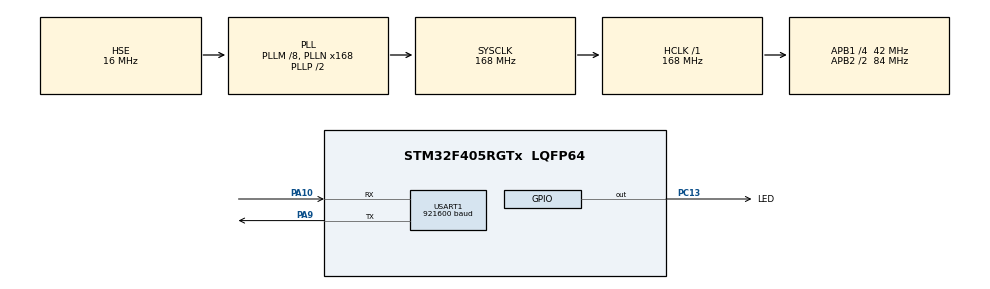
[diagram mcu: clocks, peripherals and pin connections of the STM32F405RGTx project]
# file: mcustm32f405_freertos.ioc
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FREERTOS.BinarySemaphores01=ledToggleSem,Dynamic,NULL;tickSem,Dynamic,NULL
FREERTOS.Events01=myEvent01,Dynamic,NULL
FREERTOS.Tasks01=defaultTask,24,128,StartDefaultTask,Default,NULL,Dynamic,NULL,NULL;ledTask,8,128,StartLedTask,Default,NULL,Dynamic,NULL,NULL;tickTask,8,128,StartTickTask,Default,NULL,Dynamic,NULL,NULL
FREERTOS.configUSE_NEWLIB_REENTRANT=1
Mcu.Family=STM32F4
Mcu.Name=STM32F405RGTx
Mcu.Package=LQFP64
NVIC.PriorityGroup=NVIC_PRIORITYGROUP_4
NVIC.TIM8_TRG_COM_TIM14_IRQn=true\:15\:0\:false\:false\:true\:false\:false\:true\:true
NVIC.TimeBase=TIM8_TRG_COM_TIM14_IRQn
NVIC.TimeBaseIP=TIM14
PA10.Mode=Asynchronous
PA10.Signal=USART1_RX
PA13.Mode=Trace_Asynchronous_SW
PA13.Signal=SYS_JTMS-SWDIO
PA14.Mode=Trace_Asynchronous_SW
PA14.Signal=SYS_JTCK-SWCLK
PA9.Mode=Asynchronous
PA9.Signal=USART1_TX
PB3.Mode=Trace_Asynchronous_SW
PB3.Signal=SYS_JTDO-SWO
PC13-ANTI_TAMP.GPIO_Label=LED
PC13-ANTI_TAMP.PinState=GPIO_PIN_SET
PC13-ANTI_TAMP.Signal=GPIO_Output
PH0-OSC_IN.Mode=HSE-External-Oscillator
PH0-OSC_IN.Signal=RCC_OSC_IN
PH1-OSC_OUT.Mode=HSE-External-Oscillator
PH1-OSC_OUT.Signal=RCC_OSC_OUT
ProjectManager.HeapSize=0x200
ProjectManager.StackSize=0x400
ProjectManager.TargetToolchain=STM32CubeIDE
RCC.48MHZClocksFreq_Value=84000000
RCC.AHBFreq_Value=168000000
RCC.APB1CLKDivider=RCC_HCLK_DIV4
RCC.APB1Freq_Value=42000000
RCC.APB1TimFreq_Value=84000000
RCC.APB2CLKDivider=RCC_HCLK_DIV2
RCC.APB2Freq_Value=84000000
RCC.APB2TimFreq_Value=168000000
RCC.CortexFreq_Value=168000000
RCC.HCLKFreq_Value=168000000
RCC.HSE_VALUE=16000000
RCC.HSI_VALUE=16000000
RCC.LSE_VALUE=32768
RCC.PLLM=8
RCC.PLLN=168
RCC.PLLSourceVirtual=RCC_PLLSOURCE_HSE
RCC.SYSCLKFreq_VALUE=168000000
RCC.SYSCLKSource=RCC_SYSCLKSOURCE_PLLCLK
RCC.VCOOutputFreq_Value=336000000
USART1.BaudRate=921600
USART1.VirtualMode=VM_ASYNC
VP_FREERTOS_VS_CMSIS_V2.Mode=CMSIS_V2
VP_SYS_VS_tim14.Mode=TIM14
board=custom

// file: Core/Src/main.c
/* USER CODE BEGIN Header */
/**
 ******************************************************************************
 * @file           : main.c
 * @brief          : Main program body
 ******************************************************************************
 * @attention
 *
 * Copyright (c) 2024 STMicroelectronics.
 * All rights reserved.
 *
 * This software is licensed under terms that can be found in the LICENSE file
 * in the root directory of this software component.
 * If no LICENSE file comes with this software, it is provided AS-IS.
 *
 ******************************************************************************
 */
/* USER CODE END Header */
#include "main.h"
#include "cmsis_os.h"

UART_HandleTypeDef huart1;

/* Definitions for defaultTask */
osThreadId_t defaultTaskHandle;
const osThreadAttr_t defaultTask_attributes = {
  .name = "defaultTask",
  .stack_size = 128 * 4,
  .priority = (osPriority_t) osPriorityNormal,
};
/* Definitions for ledTask */
osThreadId_t ledTaskHandle;
const osThreadAttr_t ledTask_attributes = {
  .name = "ledTask",
  .stack_size = 128 * 4,
  .priority = (osPriority_t) osPriorityLow,
};
/* Definitions for tickTask */
osThreadId_t tickTaskHandle;
const osThreadAttr_t tickTask_attributes = {
  .name = "tickTask",
  .stack_size = 128 * 4,
  .priority = (osPriority_t) osPriorityLow,
};
/* Definitions for ledToggleSem */
osSemaphoreId_t ledToggleSemHandle;
const osSemaphoreAttr_t ledToggleSem_attributes = {
  .name = "ledToggleSem"
};
/* Definitions for tickSem */
osSemaphoreId_t tickSemHandle;
const osSemaphoreAttr_t tickSem_attributes = {
  .name = "tickSem"
};
/* Definitions for myEvent01 */
osEventFlagsId_t myEvent01Handle;
const osEventFlagsAttr_t myEvent01_attributes = {
  .name = "myEvent01"
};

void SystemClock_Config(void);
static void MX_GPIO_Init(void);
static void MX_USART1_UART_Init(void);
void StartDefaultTask(void *argument);
void StartLedTask(void *argument);
void StartTickTask(void *argument);

/* USER CODE BEGIN 0 */

// Send printf to uart1
int _write(int fd, char *ptr, int len) {
    HAL_StatusTypeDef hstatus;

    if (fd == 1 || fd == 2) {
        hstatus = HAL_UART_Transmit(&huart1, (uint8_t*) ptr, len, HAL_MAX_DELAY);
        if (hstatus == HAL_OK)
            return len;
        else
            return -1;
    }
    return -1;
}

/* USER CODE END 0 */

int main(void)
{

  /* MCU Configuration--------------------------------------------------------*/

  /* Reset of all peripherals, Initializes the Flash interface and the Systick. */
  HAL_Init();

  /* Configure the system clock */
  SystemClock_Config();

  /* Initialize all configured peripherals */
  MX_GPIO_Init();
  MX_USART1_UART_Init();
  /* USER CODE BEGIN 2 */

    DBG("\n\n\n--------\nStarting\n");

  /* USER CODE END 2 */

  /* Init scheduler */
  osKernelInitialize();

  /* Create the semaphores(s) */
  /* creation of ledToggleSem */
  ledToggleSemHandle = osSemaphoreNew(1, 0, &ledToggleSem_attributes);

  /* creation of tickSem */
  tickSemHandle = osSemaphoreNew(1, 0, &tickSem_attributes);

  /* Create the thread(s) */
  /* creation of defaultTask */
  defaultTaskHandle = osThreadNew(StartDefaultTask, NULL, &defaultTask_attributes);

  /* creation of ledTask */
  ledTaskHandle = osThreadNew(StartLedTask, NULL, &ledTask_attributes);

  /* creation of tickTask */
  tickTaskHandle = osThreadNew(StartTickTask, NULL, &tickTask_attributes);

  /* Create the event(s) */
  /* creation of myEvent01 */
  myEvent01Handle = osEventFlagsNew(&myEvent01_attributes);

  /* Start scheduler */
  osKernelStart();

  /* We should never get here as control is now taken by the scheduler */
  /* Infinite loop */
    while (1)
    {

    }
}

void SystemClock_Config(void)
{
  RCC_OscInitTypeDef RCC_OscInitStruct = {0};
  RCC_ClkInitTypeDef RCC_ClkInitStruct = {0};

  /** Configure the main internal regulator output voltage
  */
  __HAL_RCC_PWR_CLK_ENABLE();
  __HAL_PWR_VOLTAGESCALING_CONFIG(PWR_REGULATOR_VOLTAGE_SCALE1);

  /** Initializes the RCC Oscillators according to the specified parameters
  * in the RCC_OscInitTypeDef structure.
  */
  RCC_OscInitStruct.OscillatorType = RCC_OSCILLATORTYPE_HSE;
  RCC_OscInitStruct.HSEState = RCC_HSE_ON;
  RCC_OscInitStruct.PLL.PLLState = RCC_PLL_ON;
  RCC_OscInitStruct.PLL.PLLSource = RCC_PLLSOURCE_HSE;
  RCC_OscInitStruct.PLL.PLLM = 8;
  RCC_OscInitStruct.PLL.PLLN = 168;
  RCC_OscInitStruct.PLL.PLLP = RCC_PLLP_DIV2;
  RCC_OscInitStruct.PLL.PLLQ = 4;
  if (HAL_RCC_OscConfig(&RCC_OscInitStruct) != HAL_OK)
  {
    Error_Handler();
  }

  /** Initializes the CPU, AHB and APB buses clocks
  */
  RCC_ClkInitStruct.ClockType = RCC_CLOCKTYPE_HCLK|RCC_CLOCKTYPE_SYSCLK
                              |RCC_CLOCKTYPE_PCLK1|RCC_CLOCKTYPE_PCLK2;
  RCC_ClkInitStruct.SYSCLKSource = RCC_SYSCLKSOURCE_PLLCLK;
  RCC_ClkInitStruct.AHBCLKDivider = RCC_SYSCLK_DIV1;
  RCC_ClkInitStruct.APB1CLKDivider = RCC_HCLK_DIV4;
  RCC_ClkInitStruct.APB2CLKDivider = RCC_HCLK_DIV2;

  if (HAL_RCC_ClockConfig(&RCC_ClkInitStruct, FLASH_LATENCY_5) != HAL_OK)
  {
    Error_Handler();
  }
}

static void MX_USART1_UART_Init(void)
{

  huart1.Instance = USART1;
  huart1.Init.BaudRate = 921600;
  huart1.Init.WordLength = UART_WORDLENGTH_8B;
  huart1.Init.StopBits = UART_STOPBITS_1;
  huart1.Init.Parity = UART_PARITY_NONE;
  huart1.Init.Mode = UART_MODE_TX_RX;
  huart1.Init.HwFlowCtl = UART_HWCONTROL_NONE;
  huart1.Init.OverSampling = UART_OVERSAMPLING_16;
  if (HAL_UART_Init(&huart1) != HAL_OK)
  {
    Error_Handler();
  }

}

static void MX_GPIO_Init(void)
{
  GPIO_InitTypeDef GPIO_InitStruct = {0};

  /* GPIO Ports Clock Enable */
  __HAL_RCC_GPIOC_CLK_ENABLE();
  __HAL_RCC_GPIOH_CLK_ENABLE();
  __HAL_RCC_GPIOA_CLK_ENABLE();
  __HAL_RCC_GPIOB_CLK_ENABLE();

  /*Configure GPIO pin Output Level */
  HAL_GPIO_WritePin(LED_GPIO_Port, LED_Pin, GPIO_PIN_SET);

  /*Configure GPIO pin : LED_Pin */
  GPIO_InitStruct.Pin = LED_Pin;
  GPIO_InitStruct.Mode = GPIO_MODE_OUTPUT_PP;
  GPIO_InitStruct.Pull = GPIO_NOPULL;
  GPIO_InitStruct.Speed = GPIO_SPEED_FREQ_LOW;
  HAL_GPIO_Init(LED_GPIO_Port, &GPIO_InitStruct);

}

void StartDefaultTask(void *argument)
{
  /* USER CODE BEGIN 5 */
    /* Infinite loop */
    for (;;) {
        osDelay(1000);
    }
  /* USER CODE END 5 */
}

void StartLedTask(void *argument)
{
  /* USER CODE BEGIN StartLedTask */
    /* Infinite loop */
    for (;;) {
        HAL_GPIO_TogglePin(LED_GPIO_Port, LED_Pin);
        osDelay(500);
    }
  /* USER CODE END StartLedTask */
}

void StartTickTask(void *argument)
{
  /* USER CODE BEGIN StartTickTask */

    static uint32_t cnt = 0;

    /* Infinite loop */
    for (;;) {

        DBG("Tick %lu\n", cnt);
        ++cnt;
        osDelay(1000);
    }
  /* USER CODE END StartTickTask */
}

void HAL_TIM_PeriodElapsedCallback(TIM_HandleTypeDef *htim)
{
  if (htim->Instance == TIM14) {
    HAL_IncTick();
  }
}

void Error_Handler(void)
{
    __disable_irq();
    while (1)
    {
    }
}
